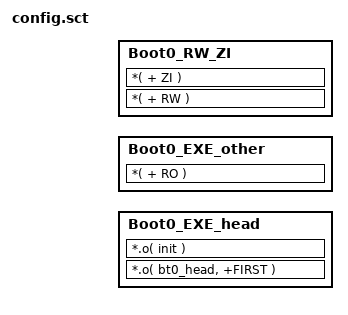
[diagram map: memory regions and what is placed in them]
#! armcc -E

;/*---------------------------------------------------------------------------*/
;/*                          --+++-- NOTE --+++--                             */
;/*             RW and ZI datas MUST NOT appear in Boot0 project!             */
;/*---------------------------------------------------------------------------*/

Boot0_load  RUN_ADDR
{
	Boot0_EXE_head  +0
	{
		*.o( bt0_head, +FIRST )
		*.o( init )
	}

	Boot0_EXE_other +0
	{
		*( + RO )
	}

	Boot0_RW_ZI  +0
	{
		*( + RW )
		*( + ZI )
	}
}

